# daric register map
Vendor: cramium
Registers are 32-bit, read-write, reset 0x0 unless marked. A register's access mark holds for its fields unless they carry their own. Offsets are from the block's base; [hi:lo] are bit positions; {n}, {i} and the like mark numbered series.

## RP_PIO
Base 0x50123000
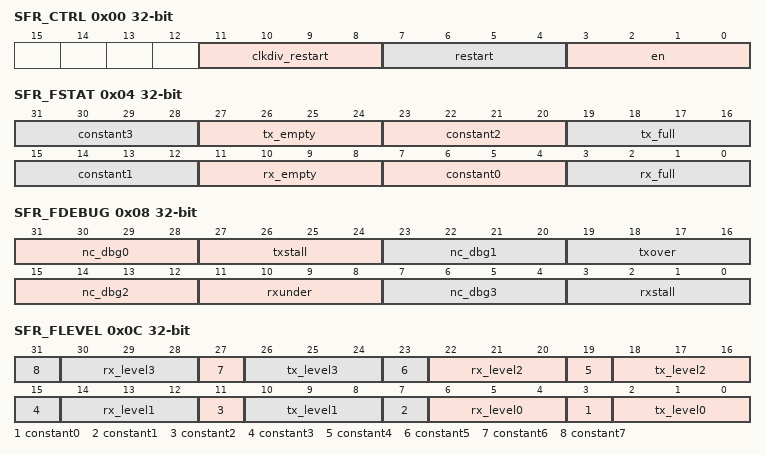
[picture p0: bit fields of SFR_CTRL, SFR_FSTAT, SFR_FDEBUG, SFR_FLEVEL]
0x00 SFR_CTRL — See file:///F:/code/cram-soc/soc_oss/ips/vexriscv/cram- soc/candidate/pio/rp_pio.sv
  [11:8] clkdiv_restart — clkdiv_restart read/write control register
  [7:4] restart — restart read/write control register
  [3:0] en — en read/write control register
0x04 SFR_FSTAT — See file:///F:/code/cram-soc/soc_oss/ips/vexriscv/cram- soc/candidate/pio/rp_pio.sv
  [8n+7:8n+4] constant{n} (n=0..3) — constant value of 0
  [27:24] tx_empty — tx_empty read only status register
  [19:16] tx_full — tx_full read only status register
  [11:8] rx_empty — rx_empty read only status register
  [3:0] rx_full — rx_full read only status register
0x08 SFR_FDEBUG — See file:///F:/code/cram-soc/soc_oss/ips/vexriscv/cram- soc/candidate/pio/rp_pio.sv
  [31-8n:28-8n] nc_dbg{n} (n=0..3) — nc_dbg{n} read/write control register
  [27:24] txstall — txstall read/write control register
  [19:16] txover — txover read/write control register
  [11:8] rxunder — rxunder read/write control register
  [3:0] rxstall — rxstall read/write control register
0x0C SFR_FLEVEL — See file:///F:/code/cram-soc/soc_oss/ips/vexriscv/cram- soc/candidate/pio/rp_pio.sv
  [4n+3] constant{n} (n=0..7) — constant value of 0
  [8n+6:8n+4] rx_level{n} (n=0..3) — rx_level[{n}] read only status register
  [8n+2:8n] tx_level{n} (n=0..3) — tx_level[{n}] read only status register
{0x10+4i} SFR_TXF{i} (i=0..3) — See file:///F:/code/cram-soc/soc_oss/ips/vexriscv/cram- soc/candidate/pio/rp_pio.sv
  [31:0] fdin — fdin read/write control register
{0x20+4i} SFR_RXF{i} (i=0..3) — See file:///F:/code/cram-soc/soc_oss/ips/vexriscv/cram- soc/candidate/pio/rp_pio.sv
  [31:0] pdout — pdout read only status register
0x30 SFR_IRQ — See file:///F:/code/cram-soc/soc_oss/ips/vexriscv/cram- soc/candidate/pio/rp_pio.sv
  [7:0] sfr_irq — sfr_irq read/write control register
0x34 SFR_IRQ_FORCE — See file:///F:/code/cram-soc/soc_oss/ips/vexriscv/cram- soc/candidate/pio/rp_pio.sv
  [7:0] sfr_irq_force — sfr_irq_force read/write control register
0x38 SFR_SYNC_BYPASS — See file:///F:/code/cram-soc/soc_oss/ips/vexriscv/cram- soc/candidate/pio/rp_pio.sv
  [31:0] sfr_sync_bypass — sfr_sync_bypass read/write control register
0x3C SFR_DBG_PADOUT — See file:///F:/code/cram-soc/soc_oss/ips/vexriscv/cram- soc/candidate/pio/rp_pio.sv
  [31:0] sfr_dbg_padout — sfr_dbg_padout read only status register
0x40 SFR_DBG_PADOE — See file:///F:/code/cram-soc/soc_oss/ips/vexriscv/cram- soc/candidate/pio/rp_pio.sv
  [31:0] sfr_dbg_padoe — sfr_dbg_padoe read only status register
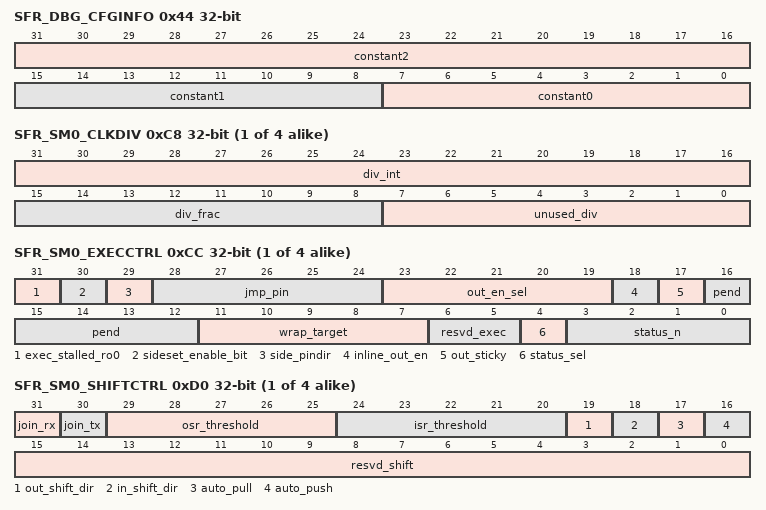
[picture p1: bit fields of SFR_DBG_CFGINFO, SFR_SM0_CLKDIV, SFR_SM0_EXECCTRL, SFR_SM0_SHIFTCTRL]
0x44 SFR_DBG_CFGINFO — See file:///F:/code/cram-soc/soc_oss/ips/vexriscv/cram- soc/candidate/pio/rp_pio.sv
  [31:16] constant2 — constant value of 32
  [15:8] constant1 — constant value of 4
  [7:0] constant0 — constant value of 4
{0x48+4i} SFR_INSTR_MEM{i} (i=0..31) — See file:///F:/code/cram-soc/soc_oss/ips/vexriscv/cram- soc/candidate/pio/rp_pio.sv
  [15:0] instr — instr read/write control register
{0xC8+0x18*i} SFR_SM{i}_CLKDIV (i=0..3) — See file:///F:/code/cram-soc/soc_oss/ips/vexriscv/cram- soc/candidate/pio/rp_pio.sv
  [31:16] div_int — div_int read/write control register
  [15:8] div_frac — div_frac read/write control register
  [7:0] unused_div — unused_div read/write control register
{0xCC+0x18*i} SFR_SM{i}_EXECCTRL (i=0..3) — See file:///F:/code/cram-soc/soc_oss/ips/vexriscv/cram- soc/candidate/pio/rp_pio.sv
  [31] exec_stalled_ro{i} — exec_stalled_ro{i} read/write control register
  [30] sideset_enable_bit — sideset_enable_bit read/write control register
  [29] side_pindir — side_pindir read/write control register
  [28:24] jmp_pin — jmp_pin read/write control register
  [23:19] out_en_sel — out_en_sel read/write control register
  [18] inline_out_en — inline_out_en read/write control register
  [17] out_sticky — out_sticky read/write control register
  [16:12] pend — pend read/write control register
  [11:7] wrap_target — wrap_target read/write control register
  [6:5] resvd_exec — resvd_exec read/write control register
  [4] status_sel — status_sel read/write control register
  [3:0] status_n — status_n read/write control register
{0xD0+0x18*i} SFR_SM{i}_SHIFTCTRL (i=0..3) — See file:///F:/code/cram-soc/soc_oss/ips/vexriscv/cram- soc/candidate/pio/rp_pio.sv
  [31] join_rx — join_rx read/write control register
  [30] join_tx — join_tx read/write control register
  [29:25] osr_threshold — osr_threshold read/write control register
  [24:20] isr_threshold — isr_threshold read/write control register
  [19] out_shift_dir — out_shift_dir read/write control register
  [18] in_shift_dir — in_shift_dir read/write control register
  [17] auto_pull — auto_pull read/write control register
  [16] auto_push — auto_push read/write control register
  [15:0] resvd_shift — resvd_shift read/write control register
{0xD4+0x18*i} SFR_SM{i}_ADDR (i=0..3) — See file:///F:/code/cram-soc/soc_oss/ips/vexriscv/cram- soc/candidate/pio/rp_pio.sv
  [4:0] pc — pc read only status register
{0xD8+0x18*i} SFR_SM{i}_INSTR (i=0..3) — See file:///F:/code/cram-soc/soc_oss/ips/vexriscv/cram- soc/candidate/pio/rp_pio.sv
  [15:0] imm_instr — imm_instr read/write control register
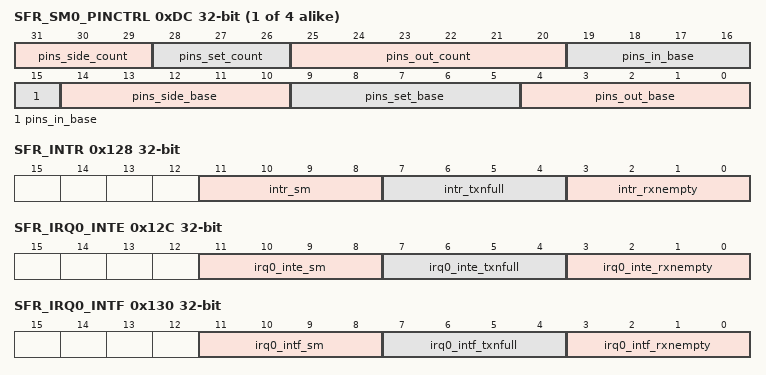
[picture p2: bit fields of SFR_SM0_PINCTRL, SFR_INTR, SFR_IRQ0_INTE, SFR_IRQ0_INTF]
{0xDC+0x18*i} SFR_SM{i}_PINCTRL (i=0..3) — See file:///F:/code/cram-soc/soc_oss/ips/vexriscv/cram- soc/candidate/pio/rp_pio.sv
  [31:29] pins_side_count — pins_side_count read/write control register
  [28:26] pins_set_count — pins_set_count read/write control register
  [25:20] pins_out_count — pins_out_count read/write control register
  [19:15] pins_in_base — pins_in_base read/write control register
  [14:10] pins_side_base — pins_side_base read/write control register
  [9:5] pins_set_base — pins_set_base read/write control register
  [4:0] pins_out_base — pins_out_base read/write control register
0x128 SFR_INTR — See file:///F:/code/cram-soc/soc_oss/ips/vexriscv/cram- soc/candidate/pio/rp_pio.sv
  [11:8] intr_sm — intr_sm read only status register
  [7:4] intr_txnfull — intr_txnfull read only status register
  [3:0] intr_rxnempty — intr_rxnempty read only status register
0x12C SFR_IRQ0_INTE — See file:///F:/code/cram-soc/soc_oss/ips/vexriscv/cram- soc/candidate/pio/rp_pio.sv
  [11:8] irq0_inte_sm — irq0_inte_sm read/write control register
  [7:4] irq0_inte_txnfull — irq0_inte_txnfull read/write control register
  [3:0] irq0_inte_rxnempty — irq0_inte_rxnempty read/write control register
0x130 SFR_IRQ0_INTF — See file:///F:/code/cram-soc/soc_oss/ips/vexriscv/cram- soc/candidate/pio/rp_pio.sv
  [11:8] irq0_intf_sm — irq0_intf_sm read/write control register
  [7:4] irq0_intf_txnfull — irq0_intf_txnfull read/write control register
  [3:0] irq0_intf_rxnempty — irq0_intf_rxnempty read/write control register
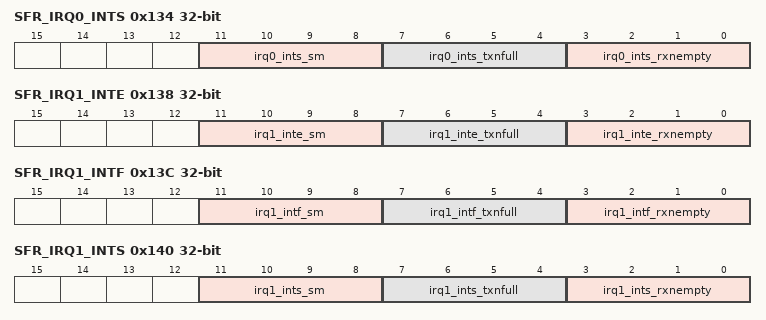
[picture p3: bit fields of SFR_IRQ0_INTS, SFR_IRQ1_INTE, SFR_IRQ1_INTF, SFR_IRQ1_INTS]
0x134 SFR_IRQ0_INTS — See file:///F:/code/cram-soc/soc_oss/ips/vexriscv/cram- soc/candidate/pio/rp_pio.sv
  [11:8] irq0_ints_sm — irq0_ints_sm read only status register
  [7:4] irq0_ints_txnfull — irq0_ints_txnfull read only status register
  [3:0] irq0_ints_rxnempty — irq0_ints_rxnempty read only status register
0x138 SFR_IRQ1_INTE — See file:///F:/code/cram-soc/soc_oss/ips/vexriscv/cram- soc/candidate/pio/rp_pio.sv
  [11:8] irq1_inte_sm — irq1_inte_sm read/write control register
  [7:4] irq1_inte_txnfull — irq1_inte_txnfull read/write control register
  [3:0] irq1_inte_rxnempty — irq1_inte_rxnempty read/write control register
0x13C SFR_IRQ1_INTF — See file:///F:/code/cram-soc/soc_oss/ips/vexriscv/cram- soc/candidate/pio/rp_pio.sv
  [11:8] irq1_intf_sm — irq1_intf_sm read/write control register
  [7:4] irq1_intf_txnfull — irq1_intf_txnfull read/write control register
  [3:0] irq1_intf_rxnempty — irq1_intf_rxnempty read/write control register
0x140 SFR_IRQ1_INTS — See file:///F:/code/cram-soc/soc_oss/ips/vexriscv/cram- soc/candidate/pio/rp_pio.sv
  [11:8] irq1_ints_sm — irq1_ints_sm read only status register
  [7:4] irq1_ints_txnfull — irq1_ints_txnfull read only status register
  [3:0] irq1_ints_rxnempty — irq1_ints_rxnempty read only status register
0x180 SFR_IO_OE_INV — See file:///F:/code/cram-soc/soc_oss/ips/vexriscv/cram- soc/candidate/pio/rp_pio.sv
  [31:0] sfr_io_oe_inv — sfr_io_oe_inv read/write control register
0x184 SFR_IO_O_INV — See file:///F:/code/cram-soc/soc_oss/ips/vexriscv/cram- soc/candidate/pio/rp_pio.sv
  [31:0] sfr_io_o_inv — sfr_io_o_inv read/write control register
0x188 SFR_IO_I_INV — See file:///F:/code/cram-soc/soc_oss/ips/vexriscv/cram- soc/candidate/pio/rp_pio.sv
  [31:0] sfr_io_i_inv — sfr_io_i_inv read/write control register
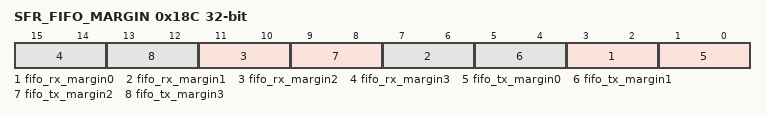
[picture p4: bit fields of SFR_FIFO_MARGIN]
0x18C SFR_FIFO_MARGIN — See file:///F:/code/cram-soc/soc_oss/ips/vexriscv/cram- soc/candidate/pio/rp_pio.sv
  [4n+3:4n+2] fifo_rx_margin{n} (n=0..3) — fifo_rx_margin{n} read/write control register
  [4n+1:4n] fifo_tx_margin{n} (n=0..3) — fifo_tx_margin{n} read/write control register
{0x190+4i} SFR_ZERO{i} (i=0..3) — See file:///F:/code/cram-soc/soc_oss/ips/vexriscv/cram- soc/candidate/pio/rp_pio.sv
  [31:0] sfr_zero{i} — sfr_zero{i} read only status register
